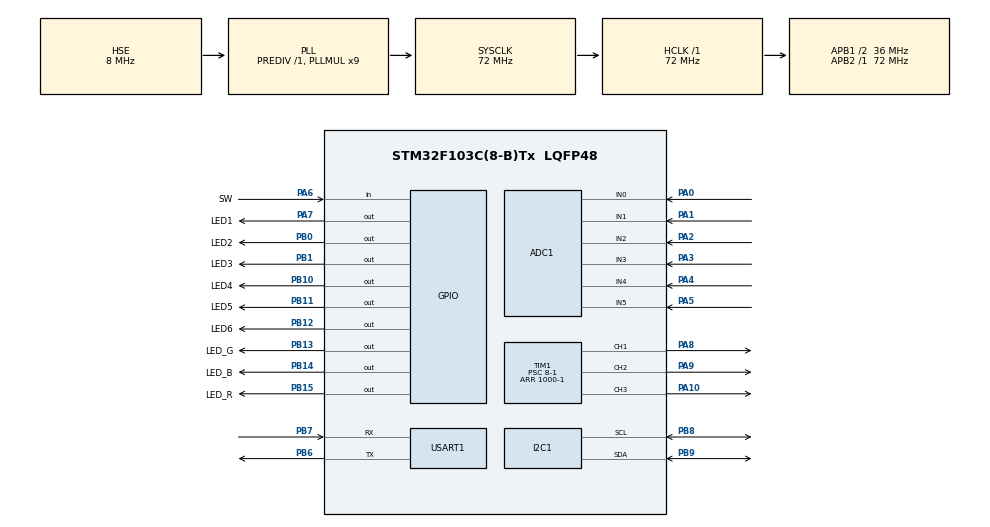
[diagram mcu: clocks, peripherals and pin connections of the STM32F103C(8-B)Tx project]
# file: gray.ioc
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ADC1.Channel-0\#ChannelRegularConversion=ADC_CHANNEL_0
ADC1.Channel-1\#ChannelRegularConversion=ADC_CHANNEL_1
ADC1.Channel-2\#ChannelRegularConversion=ADC_CHANNEL_2
ADC1.Channel-3\#ChannelRegularConversion=ADC_CHANNEL_3
ADC1.Channel-4\#ChannelRegularConversion=ADC_CHANNEL_4
ADC1.Channel-5\#ChannelRegularConversion=ADC_CHANNEL_5
ADC1.ContinuousConvMode=ENABLE
ADC1.NbrOfConversion=6
ADC1.NbrOfConversionFlag=1
ADC1.Rank-0\#ChannelRegularConversion=1
ADC1.Rank-1\#ChannelRegularConversion=2
ADC1.Rank-2\#ChannelRegularConversion=3
ADC1.Rank-3\#ChannelRegularConversion=4
ADC1.Rank-4\#ChannelRegularConversion=5
ADC1.Rank-5\#ChannelRegularConversion=6
ADC1.SamplingTime-0\#ChannelRegularConversion=ADC_SAMPLETIME_239CYCLES_5
ADC1.SamplingTime-1\#ChannelRegularConversion=ADC_SAMPLETIME_239CYCLES_5
ADC1.SamplingTime-2\#ChannelRegularConversion=ADC_SAMPLETIME_239CYCLES_5
ADC1.SamplingTime-3\#ChannelRegularConversion=ADC_SAMPLETIME_239CYCLES_5
ADC1.SamplingTime-4\#ChannelRegularConversion=ADC_SAMPLETIME_239CYCLES_5
ADC1.SamplingTime-5\#ChannelRegularConversion=ADC_SAMPLETIME_239CYCLES_5
ADC1.master=1
Dma.ADC1.0.Direction=DMA_PERIPH_TO_MEMORY
Dma.ADC1.0.Instance=DMA1_Channel1
Dma.ADC1.0.MemDataAlignment=DMA_MDATAALIGN_WORD
Dma.ADC1.0.MemInc=DMA_MINC_ENABLE
Dma.ADC1.0.Mode=DMA_CIRCULAR
Dma.ADC1.0.PeriphDataAlignment=DMA_PDATAALIGN_WORD
Dma.ADC1.0.PeriphInc=DMA_PINC_DISABLE
Dma.ADC1.0.Priority=DMA_PRIORITY_LOW
Dma.Request0=ADC1
I2C1.DualAddressMode=I2C_DUALADDRESS_ENABLE
I2C1.OwnAddress=0x70
I2C1.OwnAddress2=0x71
Mcu.Family=STM32F1
Mcu.Name=STM32F103C(8-B)Tx
Mcu.Package=LQFP48
NVIC.I2C1_ER_IRQn=true\:0\:0\:false\:false\:true\:true\:true\:true
NVIC.I2C1_EV_IRQn=true\:0\:0\:false\:false\:true\:true\:true\:true
NVIC.PriorityGroup=NVIC_PRIORITYGROUP_4
PA0-WKUP.Signal=ADCx_IN0
PA1.Signal=ADCx_IN1
PA10.Signal=S_TIM1_CH3
PA13.Mode=Serial_Wire
PA13.Signal=SYS_JTMS-SWDIO
PA14.Mode=Serial_Wire
PA14.Signal=SYS_JTCK-SWCLK
PA2.Signal=ADCx_IN2
PA3.Signal=ADCx_IN3
PA4.Signal=ADCx_IN4
PA5.Signal=ADCx_IN5
PA6.GPIO_Label=SW
PA6.GPIO_PuPd=GPIO_PULLUP
PA6.Signal=GPIO_Input
PA7.GPIO_Label=LED1
PA7.PinState=GPIO_PIN_SET
PA7.Signal=GPIO_Output
PA8.Signal=S_TIM1_CH1
PA9.Signal=S_TIM1_CH2
PB0.GPIO_Label=LED2
PB0.PinState=GPIO_PIN_SET
PB0.Signal=GPIO_Output
PB1.GPIO_Label=LED3
PB1.PinState=GPIO_PIN_SET
PB1.Signal=GPIO_Output
PB10.GPIO_Label=LED4
PB10.PinState=GPIO_PIN_SET
PB10.Signal=GPIO_Output
PB11.GPIO_Label=LED5
PB11.PinState=GPIO_PIN_SET
PB11.Signal=GPIO_Output
PB12.GPIO_Label=LED6
PB12.PinState=GPIO_PIN_SET
PB12.Signal=GPIO_Output
PB13.GPIO_Label=LED_G
PB13.PinState=GPIO_PIN_SET
PB13.Signal=GPIO_Output
PB14.GPIO_Label=LED_B
PB14.PinState=GPIO_PIN_SET
PB14.Signal=GPIO_Output
PB15.GPIO_Label=LED_R
PB15.PinState=GPIO_PIN_SET
PB15.Signal=GPIO_Output
PB6.Mode=Asynchronous
PB6.Signal=USART1_TX
PB7.Mode=Asynchronous
PB7.Signal=USART1_RX
PB8.Mode=I2C
PB8.Signal=I2C1_SCL
PB9.Mode=I2C
PB9.Signal=I2C1_SDA
PD0-OSC_IN.Mode=HSE-External-Oscillator
PD0-OSC_IN.Signal=RCC_OSC_IN
PD1-OSC_OUT.Mode=HSE-External-Oscillator
PD1-OSC_OUT.Signal=RCC_OSC_OUT
ProjectManager.HeapSize=0x200
ProjectManager.StackSize=0x400
ProjectManager.TargetToolchain=CMake
RCC.ADCPresc=RCC_ADCPCLK2_DIV6
RCC.AHBFreq_Value=72000000
RCC.APB1CLKDivider=RCC_HCLK_DIV2
RCC.APB1Freq_Value=36000000
RCC.APB1TimFreq_Value=72000000
RCC.APB2Freq_Value=72000000
RCC.APB2TimFreq_Value=72000000
RCC.HCLKFreq_Value=72000000
RCC.PLLMUL=RCC_PLL_MUL9
RCC.PLLSourceVirtual=RCC_PLLSOURCE_HSE
RCC.SYSCLKFreq_VALUE=72000000
RCC.SYSCLKSource=RCC_SYSCLKSOURCE_PLLCLK
RCC.USBFreq_Value=72000000
SH.ADCx_IN0.0=ADC1_IN0,IN0
SH.ADCx_IN1.0=ADC1_IN1,IN1
SH.ADCx_IN2.0=ADC1_IN2,IN2
SH.ADCx_IN3.0=ADC1_IN3,IN3
SH.ADCx_IN4.0=ADC1_IN4,IN4
SH.ADCx_IN5.0=ADC1_IN5,IN5
SH.S_TIM1_CH1.0=TIM1_CH1,PWM Generation1 CH1
SH.S_TIM1_CH2.0=TIM1_CH2,PWM Generation2 CH2
SH.S_TIM1_CH3.0=TIM1_CH3,PWM Generation3 CH3
TIM1.Channel-PWM\ Generation1\ CH1=TIM_CHANNEL_1
TIM1.Channel-PWM\ Generation2\ CH2=TIM_CHANNEL_2
TIM1.Channel-PWM\ Generation3\ CH3=TIM_CHANNEL_3
TIM1.OCMode_PWM-PWM\ Generation1\ CH1=TIM_OCMODE_PWM2
TIM1.OCMode_PWM-PWM\ Generation2\ CH2=TIM_OCMODE_PWM2
TIM1.OCMode_PWM-PWM\ Generation3\ CH3=TIM_OCMODE_PWM2
TIM1.Period=1000-1
TIM1.Prescaler=8-1
USART1.VirtualMode=VM_ASYNC
board=custom

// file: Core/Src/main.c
/* USER CODE BEGIN Header */
/**
  ******************************************************************************
  * @file           : main.c
  * @brief          : Main program body
  ******************************************************************************
  * @attention
  *
  * Copyright (c) 2025 STMicroelectronics.
  * All rights reserved.
  *
  * This software is licensed under terms that can be found in the LICENSE file
  * in the root directory of this software component.
  * If no LICENSE file comes with this software, it is provided AS-IS.
  *
  ******************************************************************************
  */
/* USER CODE END Header */
#include "main.h"
#include "adc.h"
#include "dma.h"
#include "i2c.h"
#include "tim.h"
#include "usart.h"
#include "gpio.h"

/* USER CODE BEGIN Includes */
#include "myCode/myMain.h"
/* USER CODE END Includes */

void SystemClock_Config(void);

int main(void)
{

  /* MCU Configuration--------------------------------------------------------*/

  /* Reset of all peripherals, Initializes the Flash interface and the Systick. */
  HAL_Init();

  /* Configure the system clock */
  SystemClock_Config();

  /* USER CODE BEGIN SysInit */
#if 0
  /* USER CODE END SysInit */

  /* Initialize all configured peripherals */
  MX_GPIO_Init();
  MX_DMA_Init();
  MX_ADC1_Init();
  MX_I2C1_Init();
  MX_TIM1_Init();
  MX_USART1_UART_Init();
  /* USER CODE BEGIN 2 */
#endif
  MX_GPIO_Init();
  MX_DMA_Init();
  MX_ADC1_Init();
  // MX_I2C1_Init();
  MX_TIM1_Init();
  MX_USART1_UART_Init();

  setup();
  /* USER CODE END 2 */

  /* Infinite loop */
  /* USER CODE BEGIN WHILE */
  while (1)
  {
    loop();
    /* USER CODE END WHILE */

  }
}

void SystemClock_Config(void)
{
  RCC_OscInitTypeDef RCC_OscInitStruct = {0};
  RCC_ClkInitTypeDef RCC_ClkInitStruct = {0};
  RCC_PeriphCLKInitTypeDef PeriphClkInit = {0};

  /** Initializes the RCC Oscillators according to the specified parameters
  * in the RCC_OscInitTypeDef structure.
  */
  RCC_OscInitStruct.OscillatorType = RCC_OSCILLATORTYPE_HSE;
  RCC_OscInitStruct.HSEState = RCC_HSE_ON;
  RCC_OscInitStruct.HSEPredivValue = RCC_HSE_PREDIV_DIV1;
  RCC_OscInitStruct.HSIState = RCC_HSI_ON;
  RCC_OscInitStruct.PLL.PLLState = RCC_PLL_ON;
  RCC_OscInitStruct.PLL.PLLSource = RCC_PLLSOURCE_HSE;
  RCC_OscInitStruct.PLL.PLLMUL = RCC_PLL_MUL9;
  if (HAL_RCC_OscConfig(&RCC_OscInitStruct) != HAL_OK)
  {
    Error_Handler();
  }

  /** Initializes the CPU, AHB and APB buses clocks
  */
  RCC_ClkInitStruct.ClockType = RCC_CLOCKTYPE_HCLK|RCC_CLOCKTYPE_SYSCLK
                              |RCC_CLOCKTYPE_PCLK1|RCC_CLOCKTYPE_PCLK2;
  RCC_ClkInitStruct.SYSCLKSource = RCC_SYSCLKSOURCE_PLLCLK;
  RCC_ClkInitStruct.AHBCLKDivider = RCC_SYSCLK_DIV1;
  RCC_ClkInitStruct.APB1CLKDivider = RCC_HCLK_DIV2;
  RCC_ClkInitStruct.APB2CLKDivider = RCC_HCLK_DIV1;

  if (HAL_RCC_ClockConfig(&RCC_ClkInitStruct, FLASH_LATENCY_2) != HAL_OK)
  {
    Error_Handler();
  }
  PeriphClkInit.PeriphClockSelection = RCC_PERIPHCLK_ADC;
  PeriphClkInit.AdcClockSelection = RCC_ADCPCLK2_DIV6;
  if (HAL_RCCEx_PeriphCLKConfig(&PeriphClkInit) != HAL_OK)
  {
    Error_Handler();
  }
}

void Error_Handler(void)
{
  __disable_irq();
  while (1)
  {
  }
}
